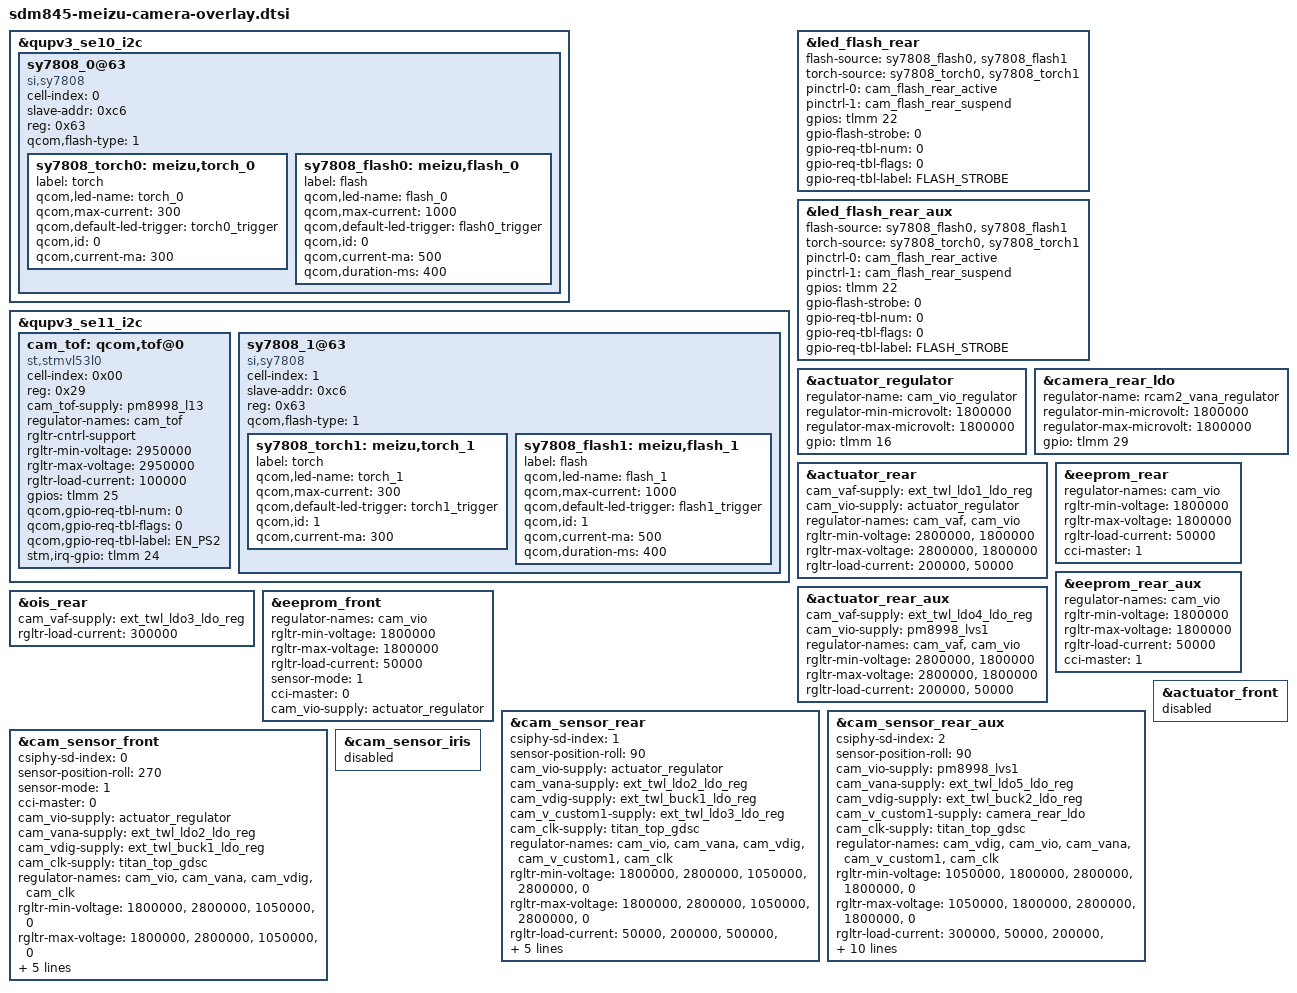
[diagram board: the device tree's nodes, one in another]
/* Copyright (c) 2022, MeizuCustoms enthusiasts
 *
 * This program is free software; you can redistribute it and/or modify
 * it under the terms of the GNU General Public License version 2 and
 * only version 2 as published by the Free Software Foundation.
 *
 * This program is distributed in the hope that it will be useful,
 * but WITHOUT ANY WARRANTY; without even the implied warranty of
 * MERCHANTABILITY or FITNESS FOR A PARTICULAR PURPOSE.  See the
 * GNU General Public License for more details.
 */

&qupv3_se10_i2c {
    status = "ok";

    sy7808_0@63 {
        cell-index = <0>;
        slave-addr = <0xc6>;
        reg = <0x63>;
        compatible = "si,sy7808";
        qcom,flash-type = <1>;

        sy7808_torch0: meizu,torch_0 {
            label = "torch";
            qcom,led-name = "torch_0";
            qcom,max-current = <300>;
            qcom,default-led-trigger = "torch0_trigger";
            qcom,id = <0>;
            qcom,current-ma = <300>;
        };

        sy7808_flash0: meizu,flash_0 {
            label = "flash";
            qcom,led-name = "flash_0";
            qcom,max-current = <1000>;
            qcom,default-led-trigger = "flash0_trigger";
            qcom,id = <0>;
            qcom,current-ma = <500>;
            qcom,duration-ms = <400>;
        };
    };
};

&qupv3_se11_i2c {
    status = "ok";

    cam_tof: qcom,tof@0 {
        cell-index = <0x00>;
        reg = <0x29>;
        compatible = "st,stmvl53l0";
        cam_tof-supply = <&pm8998_l13>;
        regulator-names = "cam_tof";
        rgltr-cntrl-support;
        rgltr-min-voltage = <2950000>;
        rgltr-max-voltage = <2950000>;
        rgltr-load-current = <100000>;
        gpios = <&tlmm 25 0x0>;
        qcom,gpio-req-tbl-num = <0>;
        qcom,gpio-req-tbl-flags = <0>;
        qcom,gpio-req-tbl-label = "EN_PS2";
        stm,irq-gpio = <&tlmm 24 0x0>;
    };

    sy7808_1@63 {
        cell-index = <1>;
        slave-addr = <0xc6>;
        reg = <0x63>;
        compatible = "si,sy7808";
        qcom,flash-type = <1>;

        sy7808_torch1: meizu,torch_1 {
            label = "torch";
            qcom,led-name = "torch_1";
            qcom,max-current = <300>;
            qcom,default-led-trigger = "torch1_trigger";
            qcom,id = <1>;
            qcom,current-ma = <300>;
        };

        sy7808_flash1: meizu,flash_1 {
            label = "flash";
            qcom,led-name = "flash_1";
            qcom,max-current = <1000>;
            qcom,default-led-trigger = "flash1_trigger";
            qcom,id = <1>;
            qcom,current-ma = <500>;
            qcom,duration-ms = <400>;
        };
    };
};

/ {
    fragment@27 {
        __overlay__ {
            /delete-node/ qcom,camera-flash@2;
            /delete-node/ qcom,camera-flash@3;
            /delete-node/ gpio-regulator@2;
            /delete-node/ gpio-regulator@3;
        };
    };
};

&led_flash_rear {
    flash-source = <&sy7808_flash0 &sy7808_flash1>;
    torch-source = <&sy7808_torch0 &sy7808_torch1>;

    pinctrl-names = "flash_default";
    pinctrl-0 = <&cam_flash_rear_active>;
    pinctrl-1 = <&cam_flash_rear_suspend>;

    gpios = <&tlmm 22 0x0>;
    gpio-flash-strobe = <0>;
    gpio-req-tbl-num = <0>;
    gpio-req-tbl-flags = <0>;
    gpio-req-tbl-label = "FLASH_STROBE";
};

&led_flash_rear_aux {
    flash-source = <&sy7808_flash0 &sy7808_flash1>;
    torch-source = <&sy7808_torch0 &sy7808_torch1>;

    pinctrl-names = "flash_default";
    pinctrl-0 = <&cam_flash_rear_active>;
    pinctrl-1 = <&cam_flash_rear_suspend>;

    gpios = <&tlmm 22 0x0>;
    gpio-flash-strobe = <0>;
    gpio-req-tbl-num = <0>;
    gpio-req-tbl-flags = <0>;
    gpio-req-tbl-label = "FLASH_STROBE";
};

&actuator_regulator {
    regulator-name = "cam_vio_regulator";
    regulator-min-microvolt = <1800000>;
    regulator-max-microvolt = <1800000>;

    gpio = <&tlmm 16 0x0>;

    /delete-property/ regulator-enable-ramp-delay;
};

&camera_rear_ldo {
    regulator-name = "rcam2_vana_regulator";
    regulator-min-microvolt = <1800000>;
    regulator-max-microvolt = <1800000>;

    gpio = <&tlmm 29 0x0>;

    /delete-property/ regulator-enable-ramp-delay;
    /delete-property/ pinctrl-names;
    /delete-property/ pinctrl-0;
};

&actuator_rear {
    cam_vaf-supply = <&ext_twl_ldo1_ldo_reg>;
    cam_vio-supply = <&actuator_regulator>;
    regulator-names = "cam_vaf", "cam_vio";
    rgltr-min-voltage = <2800000>, <1800000>;
    rgltr-max-voltage = <2800000>, <1800000>;
    rgltr-load-current = <200000>, <50000>;
};

&actuator_rear_aux {
    cam_vaf-supply = <&ext_twl_ldo4_ldo_reg>;
    cam_vio-supply = <&pm8998_lvs1>;
    regulator-names = "cam_vaf", "cam_vio";
    rgltr-min-voltage = <2800000>, <1800000>;
    rgltr-max-voltage = <2800000>, <1800000>;
    rgltr-load-current = <200000>, <50000>;
};

&ois_rear {
    cam_vaf-supply = <&ext_twl_ldo3_ldo_reg>;
    rgltr-load-current = <300000>;
};

&eeprom_rear {
    regulator-names = "cam_vio";
    rgltr-min-voltage = <1800000>;
    rgltr-max-voltage = <1800000>;
    rgltr-load-current = <50000>;
    cci-master = <1>;

    /delete-property/ gpio-no-mux;
    /delete-property/ pinctrl-names;
    /delete-property/ pinctrl-0;
    /delete-property/ pinctrl-1;
    /delete-property/ gpios;
    /delete-property/ gpio-reset;
    /delete-property/ gpio-vana;
    /delete-property/ gpio-req-tbl-num;
    /delete-property/ gpio-req-tbl-flags;
    /delete-property/ gpio-req-tbl-label;
    /delete-property/ clocks;
    /delete-property/ clock-names;
    /delete-property/ clock-cntl-level;
    /delete-property/ clock-rates;
    /delete-property/ cam_vana-supply;
    /delete-property/ cam_vdig-supply;
    /delete-property/ cam_clk-supply;
    /delete-property/ cam_vaf-supply;
};

&eeprom_rear_aux {
    regulator-names = "cam_vio";
    rgltr-min-voltage = <1800000>;
    rgltr-max-voltage = <1800000>;
    rgltr-load-current = <50000>;
    cci-master = <1>;

    /delete-property/ gpio-no-mux;
    /delete-property/ pinctrl-names;
    /delete-property/ pinctrl-0;
    /delete-property/ pinctrl-1;
    /delete-property/ gpios;
    /delete-property/ gpio-reset;
    /delete-property/ gpio-vana;
    /delete-property/ gpio-req-tbl-num;
    /delete-property/ gpio-req-tbl-flags;
    /delete-property/ gpio-req-tbl-label;
    /delete-property/ clocks;
    /delete-property/ clock-names;
    /delete-property/ clock-cntl-level;
    /delete-property/ clock-rates;
    /delete-property/ cam_vana-supply;
    /delete-property/ cam_vdig-supply;
    /delete-property/ cam_clk-supply;
    /delete-property/ cam_vaf-supply;
};

&eeprom_front {
    regulator-names = "cam_vio";
    rgltr-min-voltage = <1800000>;
    rgltr-max-voltage = <1800000>;
    rgltr-load-current = <50000>;
    sensor-mode = <1>;
    cci-master = <0>;

    cam_vio-supply = <&actuator_regulator>;

    /delete-property/ gpio-no-mux;
    /delete-property/ pinctrl-names;
    /delete-property/ pinctrl-0;
    /delete-property/ pinctrl-1;
    /delete-property/ gpios;
    /delete-property/ gpio-reset;
    /delete-property/ gpio-vana;
    /delete-property/ gpio-req-tbl-num;
    /delete-property/ gpio-req-tbl-flags;
    /delete-property/ gpio-req-tbl-label;
    /delete-property/ clocks;
    /delete-property/ clock-names;
    /delete-property/ clock-cntl-level;
    /delete-property/ clock-rates;
    /delete-property/ cam_vana-supply;
    /delete-property/ cam_vdig-supply;
    /delete-property/ cam_clk-supply;
    /delete-property/ cam_vaf-supply;
};

&cam_sensor_rear {
    csiphy-sd-index = <1>;
    sensor-position-roll = <90>;

    cam_vio-supply = <&actuator_regulator>;
    cam_vana-supply = <&ext_twl_ldo2_ldo_reg>;
    cam_vdig-supply = <&ext_twl_buck1_ldo_reg>;
    cam_v_custom1-supply = <&ext_twl_ldo3_ldo_reg>;
    cam_clk-supply = <&titan_top_gdsc>;

    regulator-names = "cam_vio", "cam_vana", "cam_vdig", "cam_v_custom1", "cam_clk";
    rgltr-min-voltage = <1800000>, <2800000>, <1050000>, <2800000>, <0>;
    rgltr-max-voltage = <1800000>, <2800000>, <1050000>, <2800000>, <0>;
    rgltr-load-current = <50000>, <200000>, <500000>, <300000>, <0>;

    gpios = <&tlmm 13 0x0>, <&tlmm 80 0x0>;
    gpio-req-tbl-num = <0>, <1>;
    gpio-req-tbl-flags = <1>, <0>;
    gpio-req-tbl-label = "CAMIF_MCLK0", "CAM_RESET0";

    /delete-property/ gpio-vana;
};

&cam_sensor_rear_aux {
    csiphy-sd-index = <2>;
    sensor-position-roll = <90>;

    cam_vio-supply = <&pm8998_lvs1>;
    cam_vana-supply = <&ext_twl_ldo5_ldo_reg>;
    cam_vdig-supply = <&ext_twl_buck2_ldo_reg>;
    cam_v_custom1-supply = <&camera_rear_ldo>;
    cam_clk-supply = <&titan_top_gdsc>;

    regulator-names = "cam_vdig", "cam_vio", "cam_vana", "cam_v_custom1", "cam_clk";
    rgltr-min-voltage = <1050000>, <1800000>, <2800000>, <1800000>, <0>;
    rgltr-max-voltage = <1050000>, <1800000>, <2800000>, <1800000>, <0>;
    rgltr-load-current = <300000>, <50000>, <200000>, <100000>, <0>;

    pinctrl-names = "cam_default", "cam_suspend";
    pinctrl-0 = <&cam_sensor_mclk1_active
            &cam_sensor_rear2_active>;
    pinctrl-1 = <&cam_sensor_mclk1_suspend
            &cam_sensor_rear2_suspend>;

    gpios = <&tlmm 14 0x0>, <&tlmm 23 0x0>;
    gpio-req-tbl-num = <0>, <1>;
    gpio-req-tbl-flags = <1>, <0>;
    gpio-req-tbl-label = "CAMIF_MCLK1", "CAM_RESET1";

    led-flash-src = <>;

    /delete-property/ gpio-vana;
};

&cam_sensor_front {
    csiphy-sd-index = <0>;
    sensor-position-roll = <270>;
    sensor-mode = <1>;
    cci-master = <0>;

    cam_vio-supply = <&actuator_regulator>;
    cam_vana-supply = <&ext_twl_ldo2_ldo_reg>;
    cam_vdig-supply = <&ext_twl_buck1_ldo_reg>;
    cam_clk-supply = <&titan_top_gdsc>;

    regulator-names = "cam_vio", "cam_vana", "cam_vdig", "cam_clk";
    rgltr-min-voltage = <1800000>, <2800000>, <1050000>, <0>;
    rgltr-max-voltage = <1800000>, <2800000>, <1050000>, <0>;
    rgltr-load-current = <50000>, <200000>, <500000>, <0>;

    gpios = <&tlmm 15 0x0>, <&tlmm 9 0x0>;
    gpio-req-tbl-num = <0>, <1>;
    gpio-req-tbl-flags = <1>, <0>;
    gpio-req-tbl-label = "CAMIF_MCLK2", "CAM_RESET2";

    /delete-property/ led-flash-src;
    /delete-property/ actuator-src;
    /delete-property/ gpio-vana;
};

&cam_sensor_iris {
    status = "disabled";

    /delete-property/ led-flash-src;
    /delete-property/ cam_vio-supply;
    /delete-property/ cam_vana-supply;
    /delete-property/ cam_vdig-supply;
    /delete-property/ cam_clk-supply;
    /delete-property/ regulator-names;
    /delete-property/ rgltr-cntrl-support;
    /delete-property/ rgltr-min-voltage;
    /delete-property/ rgltr-max-voltage;
    /delete-property/ rgltr-load-current;
    /delete-property/ gpio-no-mux;
    /delete-property/ pinctrl-names;
    /delete-property/ pinctrl-0;
    /delete-property/ pinctrl-1;
    /delete-property/ gpios;
    /delete-property/ gpio-reset;
    /delete-property/ gpio-req-tbl-num;
    /delete-property/ gpio-req-tbl-flags;
    /delete-property/ gpio-req-tbl-label;
    /delete-property/ sensor-mode;
    /delete-property/ cci-master;
    /delete-property/ clocks;
    /delete-property/ clock-names;
    /delete-property/ clock-cntl-level;
    /delete-property/ clock-rates;
};

&actuator_front {
    status = "disabled";

    /delete-property/ cam_vaf-supply;
    /delete-property/ regulator-names;
    /delete-property/ rgltr-cntrl-support;
    /delete-property/ rgltr-min-voltage;
    /delete-property/ rgltr-max-voltage;
    /delete-property/ rgltr-load-current;
};
